# M3351 register map
File version: 1.0
Registers are 32-bit, read-write, reset 0x0 unless marked. A register's access mark holds for its fields unless they carry their own. Offsets are from the block's base; [hi:lo] are bit positions.

## SYS_NS — SYS Register Map
Base 0x50000000
0x08 SYS_IPRST0 — Peripheral Reset Control Register 0
  [0] CHIPRST — Chip One-shot Reset (Write Protect). Setting this bit will reset the whole chip, including Processor core and all peripherals, and this bit will automatically return to 0 after the 2 clock cycles. The CHIPRST is same as the POR reset, all the chip controllers are reset and the chip setting from Flash are also reload. About the difference between CHIPRST and SYSRESETREQ(AIRCR[2]), please refer to System Reset section. Note: This bit is write protected. Refer to the SYS_REGLCTL register.
    0=Chip normal operation; 1=Chip one-shot reset
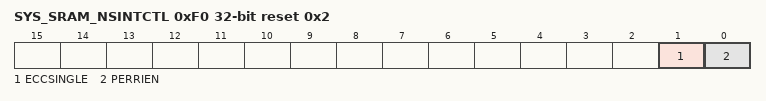
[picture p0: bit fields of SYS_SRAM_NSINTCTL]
0xF0 SYS_SRAM_NSINTCTL reset 0x2 — System SRAM Non-Secure ECC Interrupt Enable Control Register
  [1] ECCSINGLE — SRAM ECC Single Error check
    0=The SRAM ECC logic non check single-bit error; 1=The SRAM ECC logic checks for single-bit error
  [0] PERRIEN — SRAM ECC Check Error Interrupt Enable Bit
    0=SRAM ECC check error interrupt Disabled; 1=SRAM ECC check error interrupt Enabled
0xF4 SYS_SRAM_NSSTATUS — System SRAM Non-Secure ECC Status Register
  [0] PERRIF — SRAM Parity Check Error Flag. This bit indicates the System SRAM parity error occurred. Write 1 to clear this to 0. Note: This function only works if ECCEN set to 1.
    0=No System SRAM ECC error; 1=System SRAM ECC error occur
0xF8 SYS_SRAM_NSERRADDR ro — System SRAM Non-Secure ECC Error Address Register
  [31:0] ERRADDR — System SRAM ECC Error Address (Read Only). This register shows system SRAM ECC error byte address. *This function only works if ECCEN set to 1.
0x100 SYS_REGLCTL_NS — Register Lock Control Register
  [7:0] REGLCTL — Register Lock Control Code (Write Only). Some registers have write-protection function. Writing these registers have to disable the protected function by writing the sequence value '59h', '16h', '88h' to this field. After this sequence is completed, the REGLCTL bit will be set to 1 and write-protection registers can be normal write. REGLCTL[0]. Register Lock Control Disable Index (Read Only)
    0=Write-protection Enabled for writing protected registers. Any write to the protected register is ignored; 1=Write-protection Disabled for writing protected registers

## SCU_NS — SCU Register Map
Base 0x5002F000
0x20 SCU_SRAMNSSET — SRAM Non-secure Attribution Set Register
  [19:0] SECn — Set SRAM Section n to Non-secure State. Write 1 to set SRAM section n to non-secure state. Size per section is 8 Kbytes. Secure SRAM section n is 0x2000_0000+0x2000*n to 0x2000_0000+0x2000*(n+1)-0x1. Non-secure SRAM section n is 0x3000_0000+0x2000*n to 0x3000_0000+0x2000*(n+1)-0x1. Note: This bit is write-protected by SCU_SCWP. Note: SEC16~SEC19 is only for ECC function disable.
    0=SRAM Section n is secure (default); 1=SRAM Section n is non-secure
0x2C SCU_FNSADDR ro reset not defined — Flash Non-secure Boundary Address Register
  [31:0] FNSADDR — Flash Non-secure Boundary Address. Indicate the base address of Non-secure region set in user configuration, NSCBA. Refer to FMC section for more details.
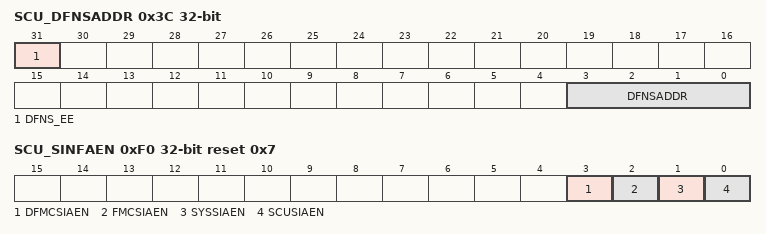
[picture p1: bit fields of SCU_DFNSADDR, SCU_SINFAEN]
0x3C SCU_DFNSADDR ro reset not defined — Data Flash Non-secure Boundary Address Register
  [31] DFNS_EE — DFMC EEPROM Non-secure State. Write 1 to set USCI1 to non-secure state.
    0=DFMC EEPROM is a secure module; 1=DFMC EEPROM is a non-secure module
  [3:0] DFNSADDR — DFlash Non-secure Boundary Address. Indicate the base address of Non-secure region set in user configuration, NSCBA. Refer to DFMC section for more details.
0xF0 SCU_SINFAEN reset 0x7 — Shared Information Access Enable Register
  [3] DFMCSIAEN — DFMC Shared Information Access Enable Bit
    0=Non-secure CPU access DFMC Shared information Disabled; 1=Non-secure CPU access DFMC Shared information Enabled
  [2] FMCSIAEN — FMC Shared Information Access Enable Bit
    0=Non-secure CPU access FMC Shared information Disabled; 1=Non-secure CPU access FMC Shared information Enabled
  [1] SYSSIAEN — SYS Shared Information Access Enable Bit. Note: Include clock information.
    0=Non-secure CPU access SYS Shared information Disabled; 1=Non-secure CPU access SYS Shared information Enabled
  [0] SCUSIAEN — SCU Shared Information Access Enable Bit
    0=Non-secure CPU access SCU Shared information Disabled; 1=Non-secure CPU access SCU Shared information Enabled
0x20C SCU_NSMSTS — Non-secure State Monitor Status Register
  [0] CURRNS — Current Core Processor Secure/Non-secure State (Read Only). Note: This bit can be used to monitor the current secure/non-secure state of the core processor, even if the non-secure state monitor counter is disabled.
    0=Core processor is in secure state; 1=Core processor is in non-secure state
